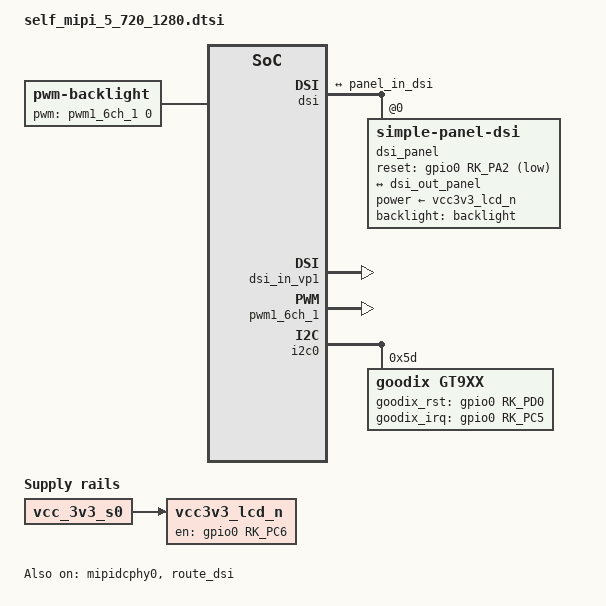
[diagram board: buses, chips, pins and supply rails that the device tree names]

/ {
	backlight: backlight {
		compatible = "pwm-backlight";
		pwms = <&pwm1_6ch_1 0 25000 0>;
		brightness-levels = <
			  0  20  20  21  21  22  22  23
			 23  24  24  25  25  26  26  27
			 27  28  28  29  29  30  30  31
			 31  32  32  33  33  34  34  35
			 35  36  36  37  37  38  38  39
			 40  41  42  43  44  45  46  47
			 48  49  50  51  52  53  54  55
			 56  57  58  59  60  61  62  63
			 64  65  66  67  68  69  70  71
			 72  73  74  75  76  77  78  79
			 80  81  82  83  84  85  86  87
			 88  89  90  91  92  93  94  95
			 96  97  98  99 100 101 102 103
			104 105 106 107 108 109 110 111
			112 113 114 115 116 117 118 119
			120 121 122 123 124 125 126 127
			128 129 130 131 132 133 134 135
			136 137 138 139 140 141 142 143
			144 145 146 147 148 149 150 151
			152 153 154 155 156 157 158 159
			160 161 162 163 164 165 166 167
			168 169 170 171 172 173 174 175
			176 177 178 179 180 181 182 183
			184 185 186 187 188 189 190 191
			192 193 194 195 196 197 198 199
			200 201 202 203 204 205 206 207
			208 209 210 211 212 213 214 215
			216 217 218 219 220 221 222 223
			224 225 226 227 228 229 230 231
			232 233 234 235 236 237 238 239
			240 241 242 243 244 245 246 247
			248 249 250 251 252 253 254 255
		>;
		default-brightness-level = <200>;
	};
	vcc3v3_lcd_n: vcc3v3-lcd0-n {
		compatible = "regulator-fixed";
		regulator-name = "vcc3v3_lcd0_n";
	    regulator-boot-on;
		enable-active-high;
		gpio = <&gpio0 RK_PC6 GPIO_ACTIVE_HIGH>;
		vin-supply = <&vcc_3v3_s0>;
	};
};

&dsi {
	status = "okay";
	//rockchip,lane-rate = <1000>;
	dsi_panel: panel@0 {
		status = "okay";
		compatible = "simple-panel-dsi";
		reg = <0>;
		backlight = <&backlight>;
		power-supply = <&vcc3v3_lcd_n>;

		reset-gpios = <&gpio0 RK_PA2 GPIO_ACTIVE_LOW>;

		reset-delay-ms = <120>;
		enable-delay-ms = <120>;
		prepare-delay-ms = <120>;
		init-delay-ms = <120>;
		unprepare-delay-ms = <60>;
		disable-delay-ms = <60>;
		
		width-mm = <62>;
		height-mm = <110>;
		
		dsi,flags = <(MIPI_DSI_MODE_VIDEO | MIPI_DSI_MODE_VIDEO_BURST |
			      MIPI_DSI_MODE_LPM | MIPI_DSI_MODE_NO_EOT_PACKET)>;
		dsi,format = <MIPI_DSI_FMT_RGB888>;
		dsi,lanes  = <4>;

		panel-init-sequence = [
			// ILI9881D 4lanes — from ILI9881D_Initial Code_4lanes.c
			// Page 3
			39 00 04 FF 98 81 03
			15 00 02 01 00
			15 00 02 02 00
			15 00 02 03 73
			15 00 02 04 00
			15 00 02 05 00
			15 00 02 06 0A
			15 00 02 07 00
			15 00 02 08 00
			15 00 02 09 01
			15 00 02 0A 00
			15 00 02 0B 00
			15 00 02 0C 01
			15 00 02 0D 00
			15 00 02 0E 00
			15 00 02 0F 1D
			15 00 02 10 1D
			15 00 02 11 00
			15 00 02 12 00
			15 00 02 13 00
			15 00 02 14 00
			15 00 02 15 00
			15 00 02 16 00
			15 00 02 17 00
			15 00 02 18 00
			15 00 02 19 00
			15 00 02 1A 00
			15 00 02 1B 00
			15 00 02 1C 00
			15 00 02 1D 00
			15 00 02 1E 40
			15 00 02 1F 80
			15 00 02 20 06
			15 00 02 21 02
			15 00 02 22 00
			15 00 02 23 00
			15 00 02 24 00
			15 00 02 25 00
			15 00 02 26 00
			15 00 02 27 00
			15 00 02 28 33
			15 00 02 29 03
			15 00 02 2A 00
			15 00 02 2B 00
			15 00 02 2C 00
			15 00 02 2D 00
			15 00 02 2E 00
			15 00 02 2F 00
			15 00 02 30 00
			15 00 02 31 00
			15 00 02 32 00
			15 00 02 33 00
			15 00 02 34 04
			15 00 02 35 00
			15 00 02 36 00
			15 00 02 37 00
			15 00 02 38 3C
			15 00 02 39 35
			15 00 02 3A 01
			15 00 02 3B 40
			15 00 02 3C 00
			15 00 02 3D 01
			15 00 02 3E 00
			15 00 02 3F 00
			15 00 02 40 00
			15 00 02 41 88
			15 00 02 42 00
			15 00 02 43 00
			15 00 02 44 1F
			15 00 02 50 01
			15 00 02 51 23
			15 00 02 52 45
			15 00 02 53 67
			15 00 02 54 89
			15 00 02 55 AB
			15 00 02 56 01
			15 00 02 57 23
			15 00 02 58 45
			15 00 02 59 67
			15 00 02 5A 89
			15 00 02 5B AB
			15 00 02 5C CD
			15 00 02 5D EF
			15 00 02 5E 11
			15 00 02 5F 01
			15 00 02 60 00
			15 00 02 61 15
			15 00 02 62 14
			15 00 02 63 0E
			15 00 02 64 0F
			15 00 02 65 0C
			15 00 02 66 0D
			15 00 02 67 06
			15 00 02 68 02
			15 00 02 69 07
			15 00 02 6A 02
			15 00 02 6B 02
			15 00 02 6C 02
			15 00 02 6D 02
			15 00 02 6E 02
			15 00 02 6F 02
			15 00 02 70 02
			15 00 02 71 02
			15 00 02 72 02
			15 00 02 73 02
			15 00 02 74 02
			15 00 02 75 01
			15 00 02 76 00
			15 00 02 77 14
			15 00 02 78 15
			15 00 02 79 0E
			15 00 02 7A 0F
			15 00 02 7B 0C
			15 00 02 7C 0D
			15 00 02 7D 06
			15 00 02 7E 02
			15 00 02 7F 07
			15 00 02 80 02
			15 00 02 81 02
			15 00 02 82 02
			15 00 02 83 02
			15 00 02 84 02
			15 00 02 85 02
			15 00 02 86 02
			15 00 02 87 02
			15 00 02 88 02
			15 00 02 89 02
			15 00 02 8A 02
			// Page 4
			39 00 04 FF 98 81 04
			15 00 02 70 00
			15 00 02 71 00
			15 00 02 82 0F
			15 00 02 84 0F
			15 00 02 85 0D
			15 00 02 32 AC
			15 00 02 8C 80
			15 00 02 3C F5
			15 00 02 B5 07
			15 00 02 31 45
			15 00 02 3A 24
			15 00 02 88 33
			// Page 1
			39 00 04 FF 98 81 01
			15 00 02 22 09
			15 00 02 31 00
			15 00 02 53 8A
			15 00 02 55 A2
			15 00 02 50 81
			15 00 02 51 85
			15 00 02 62 0D
			// Page 1
			39 00 04 FF 98 81 01
			15 00 02 A0 00
			15 00 02 A1 1A
			15 00 02 A2 28
			15 00 02 A3 13
			15 00 02 A4 16
			15 00 02 A5 29
			15 00 02 A6 1D
			15 00 02 A7 1E
			15 00 02 A8 84
			15 00 02 A9 1C
			15 00 02 AA 28
			15 00 02 AB 75
			15 00 02 AC 1A
			15 00 02 AD 19
			15 00 02 AE 4D
			15 00 02 AF 22
			15 00 02 B0 28
			15 00 02 B1 54
			15 00 02 B2 66
			15 00 02 B3 39
			// 4lane
			15 00 02 B7 02
			15 00 02 C0 00
			15 00 02 C1 1A
			15 00 02 C2 28
			15 00 02 C3 13
			15 00 02 C4 16
			15 00 02 C5 29
			15 00 02 C6 1D
			15 00 02 C7 1E
			15 00 02 C8 84
			15 00 02 C9 1C
			15 00 02 CA 28
			15 00 02 CB 75
			15 00 02 CC 1A
			15 00 02 CD 19
			15 00 02 CE 4D
			15 00 02 CF 22
			15 00 02 D0 28
			15 00 02 D1 54
			15 00 02 D2 66
			15 00 02 D3 39
			// Page 0
			39 00 04 FF 98 81 00
			// TE on
			05 00 01 35
			15 00 02 36 03
			// Sleep-out
			05 78 01 11
			// Display on
			05 78 01 29
		];

		panel-exit-sequence = [
			39 00 04 FF 98 81 00
			05 0A 01 28
			05 78 01 10
		];

		/* WKS50HD072-WCT SPEC §7 INPUT TIMING (Typ); note: ref only */
		disp_timings0: display-timings {
			native-mode = <&dsi_timing0>;
			dsi_timing0: timing0 {
				clock-frequency = <74250000>;
				hactive = <720>;
				vactive = <1280>;
				hfront-porch = <80>;
				hsync-len = <20>;
				hback-porch = <80>;
				vfront-porch = <16>;
				vsync-len = <8>;
				vback-porch = <24>;
				hsync-active = <0>;
				vsync-active = <0>;
				de-active = <0>;
				pixelclk-active = <0>;
			};
		};

		ports {
			#address-cells = <1>;
			#size-cells = <0>;

			port@0 {
				reg = <0>;
				panel_in_dsi: endpoint {
					remote-endpoint = <&dsi_out_panel>;
				};
			};
		};
	};

	ports {
		#address-cells = <1>;
		#size-cells = <0>;

		port@1 {
			reg = <1>;
			dsi_out_panel: endpoint {
				remote-endpoint = <&panel_in_dsi>;
			};
		};
	};

};

&dsi_in_vp0 {
	status = "disabled";
};

&dsi_in_vp1 {
	status = "okay";
};

&dsi_in_vp2 {
	status = "disabled";
};

&dsi_in_vopl {
	status = "disabled";
};

&mipidcphy0 {
	status = "okay";
};

&pwm1_6ch_1 {
	status = "okay";
	pinctrl-0 = <&pwm1m0_ch1>;
};


&route_dsi {
	status = "okay";
	connect = <&vp1_out_dsi>;
};

&vp1 {
	assigned-clocks = <&cru DCLK_VP1_SRC>;
	assigned-clock-parents = <&cru PLL_VPLL>;
};

&i2c0 {
	pinctrl-0 = <&i2c0m1_xfer>;
	status = "okay";

	myft5x06_0: my-ft5x06@38 {
        compatible = "focaltech,fts";
        reg = <0x38>; 
		status = "disabled";
 
        focaltech,reset-gpio = <&gpio0 RK_PD0 GPIO_ACTIVE_HIGH>;
        focaltech,irq-gpio = <&gpio0 RK_PC5 IRQ_TYPE_LEVEL_LOW>; 
 
        pinctrl-names = "default";
        pinctrl-0 = <&touch1_gpio>;

		focaltech,display-coords = <0 0 720 1280>;
		focaltech,max-touch-number = <10>;
 
    };

  	gt9xx:gt9xx@5d {
		compatible = "goodix,gt9xx";
		status = "okay";
		reg = <0x5d>;

		gtp_resolution_x = <720>;
		gtp_resolution_y = <1280>;
		gtp_int_tarigger = <1>;
		//gtp_change_x2y = <1>;
		//gtp_overturn_x = <1>;
		//gtp_overturn_y = <0>;
		gtp_send_cfg = <1>;
		gtp_touch_wakeup = <1>;
		goodix_rst_gpio = <&gpio0 RK_PD0 GPIO_ACTIVE_HIGH>;
		goodix_irq_gpio = <&gpio0 RK_PC5 IRQ_TYPE_LEVEL_LOW>; 
		pinctrl-names = "default";
		pinctrl-0 = <&touch1_gpio>;

		goodix,cfg-group0 = [
			49 D0 02 00 05 05 35 00 01 08
			1E 0A 50 3C 03 05 00 00 00 00
			00 00 00 18 1A 1E 14 8A 2A 0C
			96 98 B2 04 00 00 00 98 02 10
			00 00 00 00 00 00 00 00 00 00
			00 78 AA 94 C5 02 07 00 00 04
			96 7C 00 8D 85 00 86 8E 00 7D
			99 00 76 A4 00 76 00 00 00 00
			00 00 00 00 00 00 00 00 00 00
			00 00 00 00 00 00 00 00 00 00
			00 00 00 00 00 00 00 00 00 00
			00 00 18 16 14 12 10 0E 0C 0A
			08 06 04 02 FF FF FF FF FF FF
			FF FF FF FF FF FF FF FF FF FF
			FF FF 00 02 04 06 08 0A 0F 10
			12 13 24 22 21 20 1F 1E 1D 1C
			18 16 FF FF FF FF FF FF FF FF
			FF FF FF FF FF FF FF FF FF FF
			FF FF FF FF C8 01
		];
  	};
};

&pinctrl {
  touch1 {
    touch1_gpio: touch-gpio {
      rockchip,pins =
        <0 RK_PC5 RK_FUNC_GPIO &pcfg_pull_up>,
        <0 RK_PD0 RK_FUNC_GPIO &pcfg_pull_none>;
    };
  };
};
